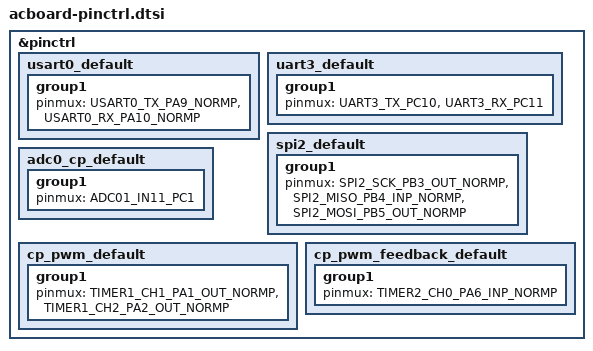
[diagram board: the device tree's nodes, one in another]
/*
 * Copyright (c) 2026
 * SPDX-License-Identifier: Apache-2.0
 */

#include <dt-bindings/pinctrl/gd32e507v(e-c)xx-pinctrl.h>

&pinctrl {
	usart0_default: usart0_default {
		group1 {
			pinmux = <USART0_TX_PA9_NORMP>, <USART0_RX_PA10_NORMP>;
		};
	};

	uart3_default: uart3_default {
		group1 {
			pinmux = <UART3_TX_PC10>, <UART3_RX_PC11>;
		};
	};

	spi2_default: spi2_default {
		group1 {
			pinmux = <SPI2_SCK_PB3_OUT_NORMP>,
				 <SPI2_MISO_PB4_INP_NORMP>,
				 <SPI2_MOSI_PB5_OUT_NORMP>;
		};
	};

	adc0_cp_default: adc0_cp_default {
		group1 {
			pinmux = <ADC01_IN11_PC1>;
		};
	};

	cp_pwm_default: cp_pwm_default {
		group1 {
			pinmux = <TIMER1_CH1_PA1_OUT_NORMP>,
				 <TIMER1_CH2_PA2_OUT_NORMP>;
		};
	};

	cp_pwm_feedback_default: cp_pwm_feedback_default {
		group1 {
			pinmux = <TIMER2_CH0_PA6_INP_NORMP>;
		};
	};
};
